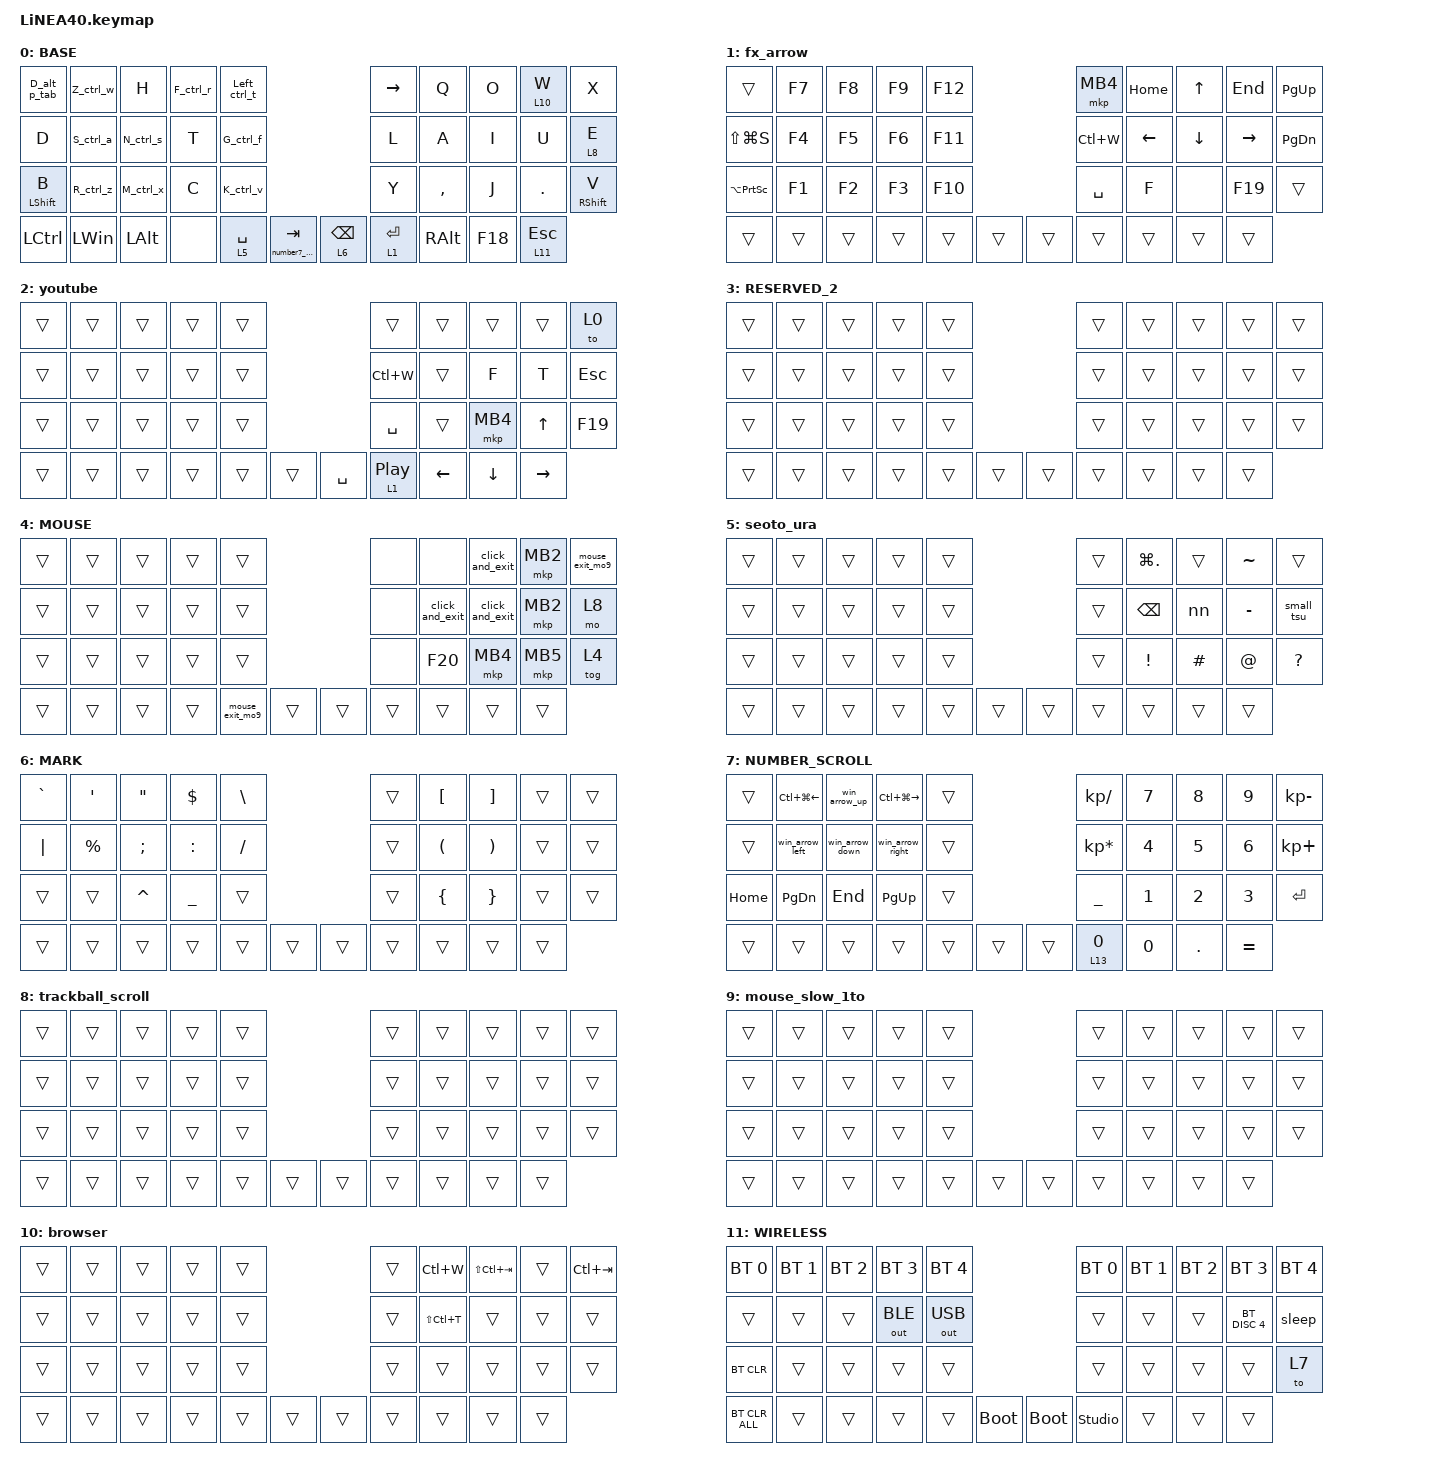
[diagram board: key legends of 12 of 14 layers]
#define ZMK_POINTING_DEFAULT_SCRL_VAL 100

#include <dt-bindings/zmk/input_transform.h>
#include <input/processors.dtsi>
#include <zephyr/dt-bindings/input/input-event-codes.h>
#include <behaviors.dtsi>
#include <dt-bindings/zmk/bt.h>
#include <dt-bindings/zmk/keys.h>
#include <dt-bindings/zmk/outputs.h>
#include <dt-bindings/zmk/pointing.h>

//mouse cursol

&mmv {
    delay-ms = <20>;
    trigger-period-ms = <5>;
    time-to-max-speed-ms = <100>;
    acceleration-exponent = <2>;
};

//mouse scroll

&msc {
    delay-ms = <3>;
    trigger-period-ms = <3>;
    time-to-max-speed-ms = <100>;
    acceleration-exponent = <0>;
};

&lt { flavor = "hold-preferred"; };

&mt { flavor = "balanced"; };

/ {
    input_processors {
        // No remainder tracking: disabled trackball motion must never accumulate.

        zip_trackball_block: zip_trackball_block {
            compatible = "zmk,input-processor-scaler";
            #input-processor-cells = <2>;
            type = <INPUT_EV_REL>;
            codes = <INPUT_REL_X INPUT_REL_Y INPUT_REL_WHEEL INPUT_REL_HWHEEL>;
        };

        zip_wheel_scaler: zip_wheel_scaler {
            compatible = "zmk,input-processor-scaler";
            #input-processor-cells = <2>;
            type = <INPUT_EV_REL>;
            codes = <INPUT_REL_WHEEL>;
            track-remainders;
        };
    };
};

&msc_input_listener {
    speed_up {
        layers = <1 13>;
        input-processors = <&zip_wheel_scaler 3 1>; //スクロールを3倍速にする
    };
};

&trackball_listener {
    // First matching override wins. Do not process the base zip_temp_layer
    // while NUMBER_SCROLL is active, including while layer 13 is held.

    number_block {
        layers = <7>;
        input-processors = <&zip_trackball_block 0 1>;
    };

    scroller {
        layers = <8>;
        input-processors =
            // Disable horizontal scrolling; remove this scaler to restore it.,,
            <&zip_x_scaler 0 1>,
            <&zip_xy_transform INPUT_TRANSFORM_Y_INVERT>,
            <&zip_xy_to_scroll_mapper>,
            <&zip_wheel_scaler 1 20>;
    };
};

/ {
    combos {
        compatible = "zmk,combos";

        DeleteKey {
            bindings = <&kp DEL>;
            key-positions = <9 8>;
            layers = <0 7>;
        };

        InsertKey {
            bindings = <&kp INS>;
            key-positions = <6 7>;
            layers = <0>;
        };

        IMEON {
            bindings = <&IME_ON_mouseout>;
            key-positions = <17 16>;
            timeout-ms = <80>;
        };

        CenterClick {
            bindings = <&mkp MB3>;
            key-positions = <18 17>;
            layers = <4>;
        };

        IMEOFF {
            bindings = <&IME_OFF_mouseout>;
            key-positions = <13 12>;
            timeout-ms = <80>;
        };

        CtrlEnter {
            bindings = <&kp LC(ENTER)>;
            key-positions = <29 28>;
            layers = <0>;
        };

        esc {
            bindings = <&kp ESCAPE>;
            key-positions = <0 1>;
            layers = <0 3>;
        };

        DeleteKey2 {
            bindings = <&kp DEL>;
            key-positions = <16 9>;
            layers = <0 7>;
        };

        window_minimum {
            bindings = <&window_minimum>;
            key-positions = <31 32>;
            layers = <0>;
        };

        CenterClick2 {
            bindings = <&mkp MB3>;
            key-positions = <7 8>;
            layers = <4>;
        };

        to_browsing {
            bindings = <&to2_youtube>;
            key-positions = <38 39 40>;
            layers = <0 4>;
            timeout-ms = <150>;
        };

        L1_home {
            bindings = <&kp HOME>;
            key-positions = <8 9>;
            layers = <1 13>;
        };

        L1_end {
            bindings = <&kp END>;
            key-positions = <18 19>;
            layers = <1 13>;
        };

        L1_less {
            bindings = <&kp LESS_THAN>;
            key-positions = <7 16>;
            layers = <1 13>;
        };

        L1_greater {
            bindings = <&kp GREATER_THAN>;
            key-positions = <7 18>;
            layers = <1 13>;
        };

        L2_greater {
            bindings = <&kp GREATER_THAN>;
            key-positions = <28 40>;
            layers = <2>;
        };

        L2_less {
            bindings = <&kp LESS_THAN>;
            key-positions = <28 38>;
            layers = <2>;
        };

        to_browsing2 {
            bindings = <&none>;
            key-positions = <38 39 40>;
            layers = <2>;
        };
    };

    behaviors {
        W_lt: W_lt {
            compatible = "zmk,behavior-hold-tap";
            label = "W_LT";
            #binding-cells = <2>;
            bindings = <&mo>, <&kp>;

            flavor = "balanced";
            tapping-term-ms = <200>;
        };

        // Keep only left-click available briefly after leaving MOUSE.

        sl_mouse: sticky_layer_for_mouse {
            compatible = "zmk,behavior-sticky-key";
            #binding-cells = <1>;
            bindings = <&mo>;
            release-after-ms = <200>;
            quick-release;
            ignore-modifiers;
        };

        re_kp: sensor_rotate_kp {
            compatible = "zmk,behavior-sensor-rotate-var";
            #sensor-binding-cells = <2>;
            bindings = <&kp>, <&kp>;
        };

        mouse_scrl: mouse_wheel_scrl {
            compatible = "zmk,behavior-sensor-rotate-var";
            #sensor-binding-cells = <2>;
            bindings = <&msc>, <&msc>;

            tap-ms = <20>;
        };

        D_alt_p_tab: D_alt_p_tab {
            compatible = "zmk,behavior-mod-morph";
            label = "D_ALT_P_TAB";
            bindings = <&win_p_tab>, <&kp TAB>;

            #binding-cells = <0>;
            mods = <(MOD_LALT|MOD_RALT)>;
            keep-mods = <(MOD_LALT|MOD_RALT)>;
        };

        win_p_tab: win_p_tab {
            compatible = "zmk,behavior-mod-morph";
            label = "WIN_P_TAB";
            bindings = <&kp P>, <&kp TAB>;

            #binding-cells = <0>;
            mods = <(MOD_RGUI|MOD_LGUI)>;
            keep-mods = <(MOD_LGUI|MOD_RGUI)>;
        };

        K_ctrl_v: K_ctrl_v {
            compatible = "zmk,behavior-mod-morph";
            label = "K_CTRL_V";
            bindings = <&kp K>, <&kp LC(V)>;

            #binding-cells = <0>;
            mods = <(MOD_LCTL)>;
            keep-mods = <(MOD_LCTL)>;
        };

        M_ctrl_x: M_ctrl_x {
            compatible = "zmk,behavior-mod-morph";
            label = "M_CTRL_X";
            bindings = <&kp M>, <&kp LC(X)>;

            #binding-cells = <0>;
            mods = <(MOD_LCTL)>;
            keep-mods = <(MOD_LCTL)>;
        };

        R_ctrl_z: R_ctrl_z {
            compatible = "zmk,behavior-mod-morph";
            label = "R_CTRL_Z";
            bindings = <&kp R>, <&kp LC(Z)>;

            #binding-cells = <0>;
            mods = <(MOD_LCTL)>;
            keep-mods = <(MOD_LCTL)>;
        };

        S_ctrl_a: S_ctrl_a {
            compatible = "zmk,behavior-mod-morph";
            label = "S_CTRL_A";
            bindings = <&kp S>, <&kp LC(A)>;

            #binding-cells = <0>;
            mods = <(MOD_LCTL)>;
            keep-mods = <(MOD_LCTL)>;
        };

        N_ctrl_s: N_ctrl_s {
            compatible = "zmk,behavior-mod-morph";
            label = "N_CTRL_S";
            bindings = <&kp N>, <&kp LC(S)>;

            #binding-cells = <0>;
            mods = <(MOD_LCTL)>;
            keep-mods = <(MOD_LCTL)>;
        };

        Left_ctrl_t: Left_ctrl_t {
            compatible = "zmk,behavior-mod-morph";
            label = "LEFT_CTRL_T";
            bindings = <&kp LEFT>, <&kp LC(T)>;

            #binding-cells = <0>;
            mods = <(MOD_LCTL)>;
            keep-mods = <(MOD_LCTL)>;
        };

        Z_ctrl_w: Z_ctrl_w {
            compatible = "zmk,behavior-mod-morph";
            label = "Z_CTRL_W";
            bindings = <&kp Z>, <&kp LC(W)>;

            #binding-cells = <0>;
            mods = <(MOD_LCTL)>;
            keep-mods = <(MOD_LCTL)>;
        };

        F_ctrl_r: F_ctrl_r {
            compatible = "zmk,behavior-mod-morph";
            label = "F_CTRL_R";
            bindings = <&kp F>, <&kp LC(R)>;

            #binding-cells = <0>;
            mods = <(MOD_LCTL)>;
            keep-mods = <(MOD_LCTL)>;
        };

        G_ctrl_f: G_ctrl_f {
            compatible = "zmk,behavior-mod-morph";
            label = "G_CTRL_F";
            bindings = <&kp G>, <&kp LC(F)>;

            #binding-cells = <0>;
            mods = <(MOD_LCTL)>;
            keep-mods = <(MOD_LCTL)>;
        };

        layer_off: layer_off {
            compatible = "zmk,behavior-toggle-layer";
            label = "LAYER_OFF";
            #binding-cells = <1>;
            toggle-mode = "off";
        };

        win_arrow_left: win_arrow_left {
            compatible = "zmk,behavior-mod-morph";
            label = "WIN_ARROW_LEFT";
            bindings = <&win_start_left>, <&kp LEFT>;

            #binding-cells = <0>;
            mods = <(MOD_LGUI)>;
            keep-mods = <(MOD_LGUI)>;
        };

        win_arrow_down: win_arrow_down {
            compatible = "zmk,behavior-mod-morph";
            label = "WIN_ARROW_DOWN";
            bindings = <&win_start_down>, <&kp DOWN>;

            #binding-cells = <0>;
            mods = <(MOD_LGUI)>;
            keep-mods = <(MOD_LGUI)>;
        };

        win_arrow_up: win_arrow_up {
            compatible = "zmk,behavior-mod-morph";
            label = "WIN_ARROW_UP";
            bindings = <&win_start_up>, <&kp UP>;

            #binding-cells = <0>;
            mods = <(MOD_LGUI)>;
            keep-mods = <(MOD_LGUI)>;
        };

        win_arrow_right: win_arrow_right {
            compatible = "zmk,behavior-mod-morph";
            label = "WIN_ARROW_RIGHT";
            bindings = <&win_start_right>, <&kp RIGHT>;

            #binding-cells = <0>;
            mods = <(MOD_LGUI)>;
            keep-mods = <(MOD_LGUI)>;
        };

        number7_lt: number7_lt {
            compatible = "zmk,behavior-hold-tap";
            label = "NUMBER7_LT";
            bindings = <&number7_hold>, <&kp>;

            #binding-cells = <2>;
            tapping-term-ms = <200>;
        };
    };

    macros {
        // Hold MB1 until release for dragging, then return to BASE.

        click_and_exit: click_and_exit {
            compatible = "zmk,behavior-macro";
            #binding-cells = <0>;
            label = "CLICK_AND_EXIT";
            wait-ms = <0>;
            tap-ms = <0>;
            bindings =
                <&macro_press>,
                <&mkp MB1>,
                <&macro_pause_for_release>,
                <&macro_release>,
                <&mkp MB1>,
                <&macro_tap>,
                <&to 0 &sl_mouse 12>;
        };

        nn: nn {
            compatible = "zmk,behavior-macro";
            #binding-cells = <0>;
            bindings = <&kp V &kp N>;
            label = "NN";
        };

        small_tsu: small_tsu {
            compatible = "zmk,behavior-macro";
            #binding-cells = <0>;
            bindings = <&kp L &kp T &kp U>;
            label = "SMALL_TSU";
        };

        sleep: sleep {
            compatible = "zmk,behavior-macro";
            #binding-cells = <0>;
            bindings = <&kp LG(X) &kp U &kp S>;
            label = "SLEEP";
            wait-ms = <200>;
            tap-ms = <40>;
        };

        IME_ON_mouseout: IME_ON {
            compatible = "zmk,behavior-macro";
            #binding-cells = <0>;
            bindings = <&kp LANG1 &to 0>;
            label = "IME_ON";
        };

        IME_OFF_mouseout: IME_OFF {
            compatible = "zmk,behavior-macro";
            #binding-cells = <0>;
            bindings = <&kp LANGUAGE_2 &to 0>;
            label = "IME_OFF";
        };

        window_minimum: window_minimum {
            compatible = "zmk,behavior-macro";
            #binding-cells = <0>;
            bindings = <&kp LA(SPACE) &kp N>;
            label = "WINDOW_MINIMUM";
            wait-ms = <50>;
            tap-ms = <50>;
        };

        mouse_exit_mo9: mouse_exit_mo9 {
            compatible = "zmk,behavior-macro";
            #binding-cells = <0>;
            bindings =
                <&layer_off 4>,
                <&macro_press>,
                <&mo 9>,
                <&macro_pause_for_release>,
                <&macro_release>,
                <&mo 9>,
                <&macro_tap>,
                <&layer_off 4>;

            label = "MOUSE_EXIT_MO9";
            wait-ms = <0>;
            tap-ms = <0>;
        };

        win_start_left: win_start_left {
            compatible = "zmk,behavior-macro";
            #binding-cells = <0>;
            bindings = <&macro_press>, <&kp LEFT_GUI>, <&macro_tap>, <&kp LEFT>;

            label = "WIN_START_LEFT";
            wait-ms = <30>;
            tap-ms = <30>;
        };

        win_start_down: win_start_down {
            compatible = "zmk,behavior-macro";
            #binding-cells = <0>;
            bindings = <&macro_press>, <&kp LEFT_GUI>, <&macro_tap>, <&kp DOWN>;

            label = "WIN_START_DOWN";
            wait-ms = <30>;
            tap-ms = <30>;
        };

        win_start_up: win_start_up {
            compatible = "zmk,behavior-macro";
            #binding-cells = <0>;
            bindings = <&macro_press>, <&kp LEFT_GUI>, <&macro_tap>, <&kp UP>;

            label = "WIN_START_UP";
            wait-ms = <30>;
            tap-ms = <30>;
        };

        win_start_right: win_start_right {
            compatible = "zmk,behavior-macro";
            #binding-cells = <0>;
            bindings =
                <&macro_press>,
                <&kp LEFT_GUI>,
                <&macro_tap>,
                <&kp RIGHT>;

            label = "WIN_START_RIGHT";
            wait-ms = <30>;
            tap-ms = <30>;
        };

        number7_hold: number7_hold {
            compatible = "zmk,behavior-macro";
            #binding-cells = <0>;
            bindings =
                <&macro_press>,
                <&mo 7>,
                <&macro_pause_for_release>,
                <&macro_release>,
                <&kp LEFT_GUI &mo 7>;

            label = "NUMBER7_HOLD";
            wait-ms = <0>;
            tap-ms = <0>;
        };

        to2_youtube: to2_youtube {
            compatible = "zmk,behavior-macro";
            #binding-cells = <0>;
            bindings = <&to 2 &kp F19>;
            label = "TO2_YOUTUBE";
        };
    };

    keymap {
        compatible = "zmk,keymap";

        // 0: BASE

        default_layer {
            display-name = "BASE";
            bindings = <
&D_alt_p_tab      &Z_ctrl_w     &kp H         &F_ctrl_r  &Left_ctrl_t                                        &kp RIGHT    &kp Q      &kp O          &W_lt 10 W  &kp X
&kp D             &S_ctrl_a     &N_ctrl_s     &kp T      &G_ctrl_f                                           &kp L        &kp A      &kp I          &kp U       &lt 8 E
&mt LEFT_SHIFT B  &R_ctrl_z     &M_ctrl_x     &kp C      &K_ctrl_v                                           &kp Y        &kp COMMA  &kp J          &kp DOT     &mt RIGHT_SHIFT V
&kp LCTRL         &kp LEFT_WIN  &kp LEFT_ALT  &none      &lt 5 SPACE   &number7_lt 0 TAB    &lt 6 BACKSPACE  &lt 1 ENTER             &kp RIGHT_ALT  &kp F18     &lt 11 ESC
            >;

            sensor-bindings = <&mouse_scrl SCRL_DOWN SCRL_UP>;
        };

        // 1: BROWSING

        fx_arrow {
            display-name = "fx_arrow";
            bindings = <
&trans               &kp F7  &kp F8  &kp F9  &kp F12                    &mkp MB4   &kp HOME        &kp UP_ARROW    &kp END          &kp PAGE_UP
&kp LS(LG(S))        &kp F4  &kp F5  &kp F6  &kp F11                    &kp LC(W)  &kp LEFT_ARROW  &kp DOWN_ARROW  &kp RIGHT_ARROW  &kp PAGE_DOWN
&kp LA(PRINTSCREEN)  &kp F1  &kp F2  &kp F3  &kp F10                    &kp SPACE  &kp F           &none           &kp F19          &trans
&trans               &trans  &trans  &trans  &trans   &trans    &trans  &trans                     &trans          &trans           &trans
            >;

            sensor-bindings = <&mouse_scrl SCRL_DOWN SCRL_UP>;
        };

        // 2: RESERVED_1

        youtube {
            display-name = "youtube";
            bindings = <
&trans  &trans  &trans  &trans  &trans                       &trans              &trans  &trans          &trans          &to 0
&trans  &trans  &trans  &trans  &trans                       &kp LC(W)           &trans  &kp F           &kp T           &kp ESCAPE
&trans  &trans  &trans  &trans  &trans                       &kp SPACE           &trans  &mkp MB4        &kp UP_ARROW    &kp F19
&trans  &trans  &trans  &trans  &trans  &trans    &kp SPACE  &lt 1 C_PLAY_PAUSE          &kp LEFT_ARROW  &kp DOWN_ARROW  &kp RIGHT_ARROW
            >;
        };

        // 3: RESERVED_2

        reserved_2 {
            display-name = "RESERVED_2";
            bindings = <
&trans  &trans  &trans  &trans  &trans                    &trans  &trans  &trans  &trans  &trans
&trans  &trans  &trans  &trans  &trans                    &trans  &trans  &trans  &trans  &trans
&trans  &trans  &trans  &trans  &trans                    &trans  &trans  &trans  &trans  &trans
&trans  &trans  &trans  &trans  &trans  &trans    &trans  &trans          &trans  &trans  &trans
            >;
        };

        // 4: MOUSE

        mouse {
            display-name = "MOUSE";
            bindings = <
&trans  &trans  &trans  &trans  &trans                             &none   &none            &click_and_exit  &mkp MB2  &mouse_exit_mo9
&trans  &trans  &trans  &trans  &trans                             &none   &click_and_exit  &click_and_exit  &mkp MB2  &mo 8
&trans  &trans  &trans  &trans  &trans                             &none   &kp F20          &mkp MB4         &mkp MB5  &tog 4
&trans  &trans  &trans  &trans  &mouse_exit_mo9  &trans    &trans  &trans                   &trans           &trans    &trans
            >;
        };

        // 5: seoto_ura

        seoto_ura {
            display-name = "seoto_ura";
            bindings = <
&trans  &trans  &trans  &trans  &trans                    &trans  &kp LG(PERIOD)   &trans    &kp TILDE    &trans
&trans  &trans  &trans  &trans  &trans                    &trans  &kp BACKSPACE    &nn       &kp MINUS    &small_tsu
&trans  &trans  &trans  &trans  &trans                    &trans  &kp EXCLAMATION  &kp HASH  &kp AT_SIGN  &kp QMARK
&trans  &trans  &trans  &trans  &trans  &trans    &trans  &trans                   &trans    &trans       &trans
            >;
        };

        // 6: MARK

        mark {
            display-name = "MARK";
            bindings = <
&kp GRAVE  &kp SINGLE_QUOTE  &kp DOUBLE_QUOTES  &kp DOLLAR  &kp BACKSLASH                    &trans  &kp LEFT_BRACKET      &kp RIGHT_BRACKET      &trans  &trans
&kp PIPE   &kp PERCENT       &kp SEMI           &kp COLON   &kp SLASH                        &trans  &kp LEFT_PARENTHESIS  &kp RIGHT_PARENTHESIS  &trans  &trans
&trans     &trans            &kp CARET          &kp UNDER   &trans                           &trans  &kp LEFT_BRACE        &kp RIGHT_BRACE        &trans  &trans
&trans     &trans            &trans             &trans      &trans         &trans    &trans  &trans                        &trans                 &trans  &trans
            >;

            sensor-bindings = <&re_kp C_VOLUME_DOWN C_VOLUME_UP>;
        };

        // 7: NUMBER_SCROLL

        number_scroll {
            display-name = "NUMBER_SCROLL";
            bindings = <
&trans    &kp LC(LG(LEFT_ARROW))  &win_arrow_up    &kp LC(LG(RIGHT_ARROW))  &trans                    &kp KP_SLASH     &kp NUMBER_7  &kp NUMBER_8  &kp NUMBER_9  &kp KP_MINUS
&trans    &win_arrow_left         &win_arrow_down  &win_arrow_right         &trans                    &kp KP_MULTIPLY  &kp NUMBER_4  &kp NUMBER_5  &kp NUMBER_6  &kp KP_PLUS
&kp HOME  &kp PAGE_DOWN           &kp END          &kp PAGE_UP              &trans                    &kp UNDER        &kp NUMBER_1  &kp NUMBER_2  &kp NUMBER_3  &kp ENTER
&trans    &trans                  &trans           &trans                   &trans  &trans    &trans  &lt 13 NUMBER_0                &kp NUMBER_0  &kp DOT       &kp EQUAL
            >;

            sensor-bindings = <&inc_dec_kp DOWN_ARROW UP_ARROW>;
        };

        // 8: trackball_scroll

        trackball_scroll {
            display-name = "trackball_scroll";
            bindings = <
&trans  &trans  &trans  &trans  &trans                    &trans  &trans  &trans  &trans  &trans
&trans  &trans  &trans  &trans  &trans                    &trans  &trans  &trans  &trans  &trans
&trans  &trans  &trans  &trans  &trans                    &trans  &trans  &trans  &trans  &trans
&trans  &trans  &trans  &trans  &trans  &trans    &trans  &trans          &trans  &trans  &trans
            >;
        };

        // 9: mouse_slow_1to

        mouse_slow_1to {
            display-name = "mouse_slow_1to";
            bindings = <
&trans  &trans  &trans  &trans  &trans                    &trans  &trans  &trans  &trans  &trans
&trans  &trans  &trans  &trans  &trans                    &trans  &trans  &trans  &trans  &trans
&trans  &trans  &trans  &trans  &trans                    &trans  &trans  &trans  &trans  &trans
&trans  &trans  &trans  &trans  &trans  &trans    &trans  &trans          &trans  &trans  &trans
            >;
        };

        // 10: browser

        browser {
            display-name = "browser";
            bindings = <
&trans  &trans  &trans  &trans  &trans                    &trans  &kp LC(W)      &kp LS(LC(TAB))  &trans  &kp LC(TAB)
&trans  &trans  &trans  &trans  &trans                    &trans  &kp LS(LC(T))  &trans           &trans  &trans
&trans  &trans  &trans  &trans  &trans                    &trans  &trans         &trans           &trans  &trans
&trans  &trans  &trans  &trans  &trans  &trans    &trans  &trans                 &trans           &trans  &trans
            >;
        };

        // 11: WIRELESS

        wireless {
            display-name = "WIRELESS";
            bindings = <
&bt BT_SEL 0    &bt BT_SEL 1  &bt BT_SEL 2  &bt BT_SEL 3  &bt BT_SEL 4                              &bt BT_SEL 0    &bt BT_SEL 1  &bt BT_SEL 2  &bt BT_SEL 3   &bt BT_SEL 4
&trans          &trans        &trans        &out OUT_BLE  &out OUT_USB                              &trans          &trans        &trans        &bt BT_DISC 4  &sleep
&bt BT_CLR      &trans        &trans        &trans        &trans                                    &trans          &trans        &trans        &trans         &to 7
&bt BT_CLR_ALL  &trans        &trans        &trans        &trans        &bootloader    &bootloader  &studio_unlock                &trans        &trans         &trans
            >;

            sensor-bindings = <&inc_dec_kp RIGHT_ARROW LEFT_ARROW>;
        };

        // 12: CLICK_REPEAT (same left-click positions as MOUSE)

        click_repeat {
            display-name = "CLICK_REPEAT";
            bindings = <
&trans  &trans  &trans  &trans  &trans                    &trans  &trans           &click_and_exit  &trans  &trans
&trans  &trans  &trans  &trans  &trans                    &trans  &click_and_exit  &click_and_exit  &trans  &trans
&trans  &trans  &trans  &trans  &trans                    &trans  &trans           &trans           &trans  &trans
&trans  &trans  &trans  &trans  &trans  &trans    &trans  &trans                   &trans           &trans  &trans
            >;
        };

        // 13: Copy of layer 1, above NUMBER_SCROLL for momentary arrows.

        fx_arrow_number {
            display-name = "fx_arrow_number";
            bindings = <
&trans               &kp F7  &kp F8  &kp F9  &kp F12                    &mkp MB4   &kp HOME        &kp UP_ARROW    &kp END          &kp PAGE_UP
&kp LS(LG(S))        &kp F4  &kp F5  &kp F6  &kp F11                    &kp LC(W)  &kp LEFT_ARROW  &kp DOWN_ARROW  &kp RIGHT_ARROW  &kp PAGE_DOWN
&kp LA(PRINTSCREEN)  &kp F1  &kp F2  &kp F3  &kp F10                    &kp SPACE  &kp F           &none           &kp F19          &trans
&trans               &trans  &trans  &trans  &trans   &trans    &trans  &trans                     &trans          &trans           &trans
            >;

            sensor-bindings = <&mouse_scrl SCRL_DOWN SCRL_UP>;
        };
    };
};
